# STM32WB10CCU6 register map
File version: 1.0
Registers are 32-bit, access not given, reset 0x0 unless marked. A register's access mark holds for its fields unless they carry their own. Offsets are from the block's base; [hi:lo] are bit positions; {n}, {i} and the like mark numbered series.

## WWDG
Base 0x40002C00
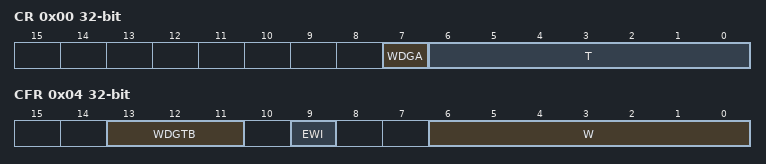
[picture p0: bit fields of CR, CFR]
0x00 CR
  [7] WDGA, [6:0] T
0x04 CFR
  [13:11] WDGTB, [9] EWI, [6:0] W
0x08 SR
  [0] EWIF

## IWDG
Base 0x40003000
0x00 KR
  [15:0] KEY
0x04 PR
  [2:0] PR
0x08 RLR
  [11:0] RL
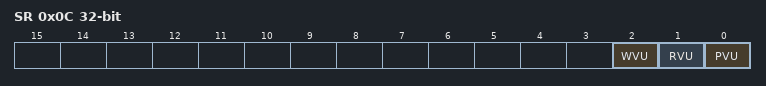
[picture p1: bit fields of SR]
0x0C SR
  [2] WVU, [1] RVU, [0] PVU
0x10 WINR
  [11:0] WIN

## I2C1
Base 0x40005400
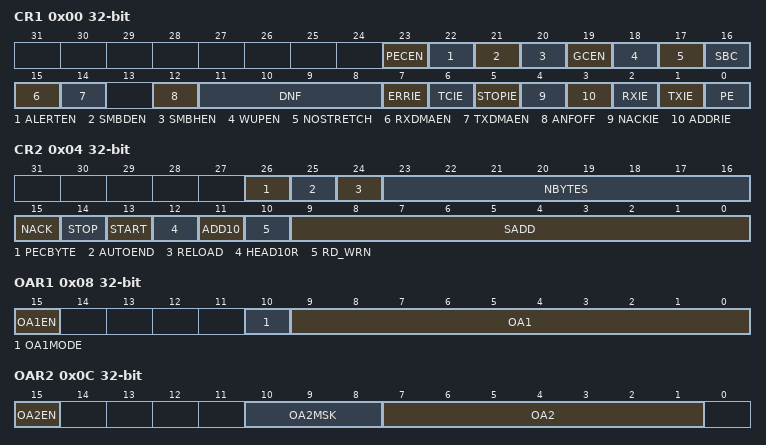
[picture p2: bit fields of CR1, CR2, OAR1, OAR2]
0x00 CR1
  [23] PECEN, [22] ALERTEN, [21] SMBDEN, [20] SMBHEN, [19] GCEN, [18] WUPEN, [17] NOSTRETCH, [16] SBC, [15] RXDMAEN, [14] TXDMAEN, [12] ANFOFF, [11:8] DNF, [7] ERRIE, [6] TCIE, [5] STOPIE, [4] NACKIE, [3] ADDRIE, [2] RXIE, [1] TXIE, [0] PE
0x04 CR2
  [26] PECBYTE, [25] AUTOEND, [24] RELOAD, [23:16] NBYTES, [15] NACK, [14] STOP, [13] START, [12] HEAD10R, [11] ADD10, [10] RD_WRN, [9:0] SADD
0x08 OAR1
  [15] OA1EN, [10] OA1MODE, [9:0] OA1
0x0C OAR2
  [15] OA2EN, [10:8] OA2MSK, [7:1] OA2
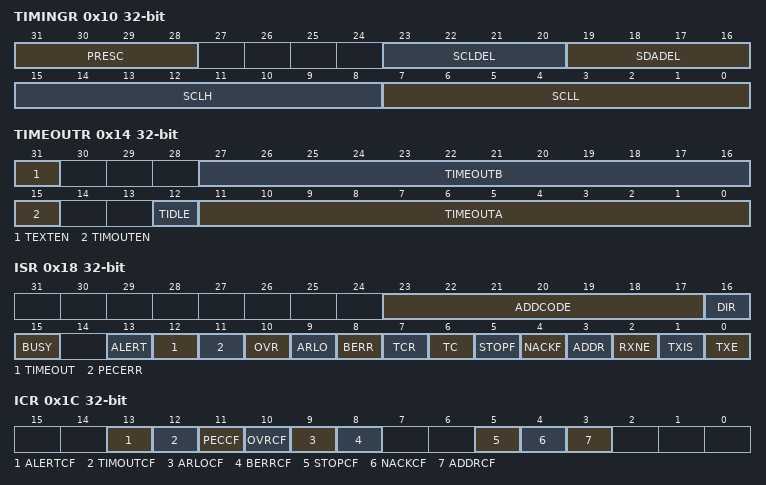
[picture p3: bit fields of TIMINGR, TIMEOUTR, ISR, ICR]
0x10 TIMINGR
  [31:28] PRESC, [23:20] SCLDEL, [19:16] SDADEL, [15:8] SCLH, [7:0] SCLL
0x14 TIMEOUTR
  [31] TEXTEN, [27:16] TIMEOUTB, [15] TIMOUTEN, [12] TIDLE, [11:0] TIMEOUTA
0x18 ISR
  [23:17] ADDCODE, [16] DIR, [15] BUSY, [13] ALERT, [12] TIMEOUT, [11] PECERR, [10] OVR, [9] ARLO, [8] BERR, [7] TCR, [6] TC, [5] STOPF, [4] NACKF, [3] ADDR, [2] RXNE, [1] TXIS, [0] TXE
0x1C ICR
  [13] ALERTCF, [12] TIMOUTCF, [11] PECCF, [10] OVRCF, [9] ARLOCF, [8] BERRCF, [5] STOPCF, [4] NACKCF, [3] ADDRCF
0x20 PECR
  [7:0] PEC
0x24 RXDR
  [7:0] RXDATA
0x28 TXDR
  [7:0] TXDATA

## LPTIM1
Base 0x40007C00
Same registers: LPTIM2 0x40009400
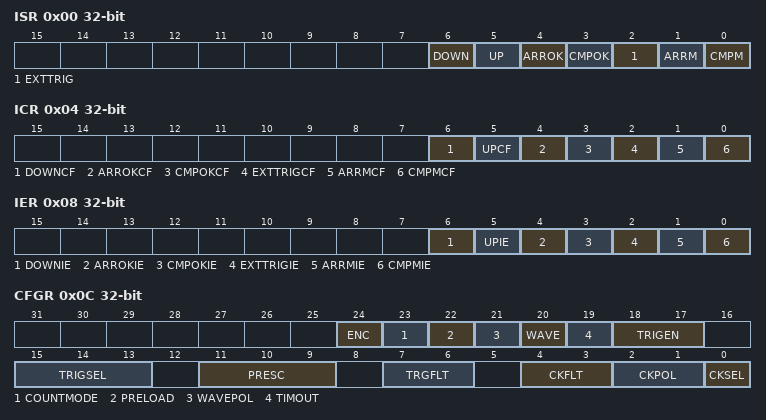
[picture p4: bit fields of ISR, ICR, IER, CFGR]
0x00 ISR
  [6] DOWN, [5] UP, [4] ARROK, [3] CMPOK, [2] EXTTRIG, [1] ARRM, [0] CMPM
0x04 ICR
  [6] DOWNCF, [5] UPCF, [4] ARROKCF, [3] CMPOKCF, [2] EXTTRIGCF, [1] ARRMCF, [0] CMPMCF
0x08 IER
  [6] DOWNIE, [5] UPIE, [4] ARROKIE, [3] CMPOKIE, [2] EXTTRIGIE, [1] ARRMIE, [0] CMPMIE
0x0C CFGR
  [24] ENC, [23] COUNTMODE, [22] PRELOAD, [21] WAVEPOL, [20] WAVE, [19] TIMOUT, [18:17] TRIGEN, [15:13] TRIGSEL, [11:9] PRESC, [7:6] TRGFLT, [4:3] CKFLT, [2:1] CKPOL, [0] CKSEL
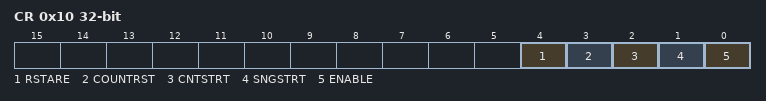
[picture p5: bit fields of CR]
0x10 CR
  [4] RSTARE, [3] COUNTRST, [2] CNTSTRT, [1] SNGSTRT, [0] ENABLE
0x14 CMP
  [15:0] CMP
0x18 ARR
  [15:0] ARR
0x1C CNT
  [15:0] CNT

## SYSCFG
Base 0x40010000
0x00 MEMRMP
  [2:0] MEM_MODE
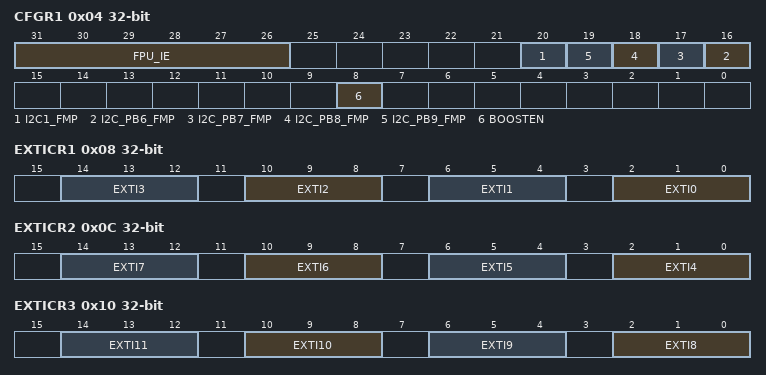
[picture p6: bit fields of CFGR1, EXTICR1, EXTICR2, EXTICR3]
0x04 CFGR1
  [31:26] FPU_IE, [20] I2C1_FMP, [n+10] I2C_PB{n}_FMP (n=6..9), [8] BOOSTEN
0x08 EXTICR1
  [4n+2:4n] EXTI{n} (n=0..3)
0x0C EXTICR2
  [4n-14:4n-16] EXTI{n} (n=4..7)
0x10 EXTICR3
  [4n-30:4n-32] EXTI{n} (n=8..11)
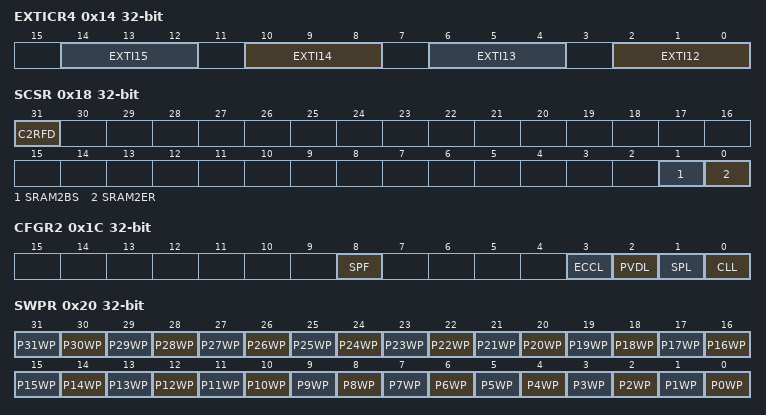
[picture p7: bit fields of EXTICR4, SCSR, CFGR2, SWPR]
0x14 EXTICR4
  [4n-46:4n-48] EXTI{n} (n=12..15)
0x18 SCSR
  [31] C2RFD, [1] SRAM2BS, [0] SRAM2ER
0x1C CFGR2
  [8] SPF, [3] ECCL, [2] PVDL, [1] SPL, [0] CLL
0x20 SWPR
  [n] P{n}WP (n=0..31)
0x24 SKR
  [7:0] KEY
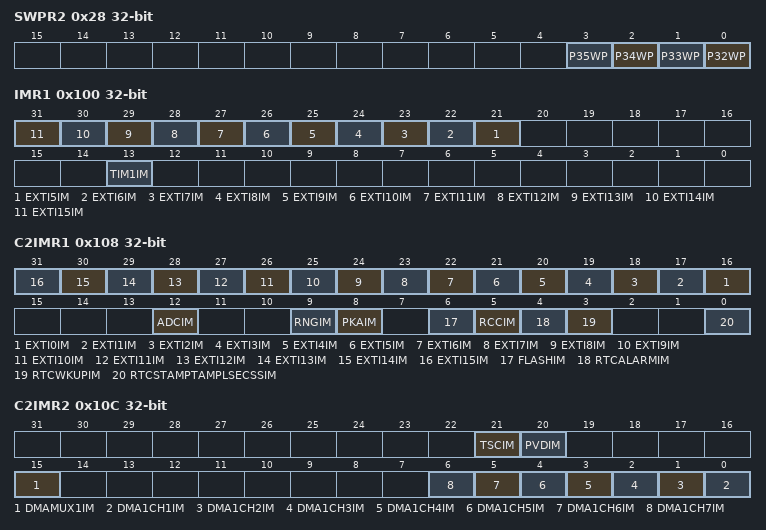
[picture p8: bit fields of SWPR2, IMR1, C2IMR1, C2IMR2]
0x28 SWPR2
  [n-32] P{n}WP (n=32..35)
0x100 IMR1
  [n+16] EXTI{n}IM (n=5..15), [13] TIM1IM
0x104 IMR2
  [20] PVDIM
0x108 C2IMR1
  [n+16] EXTI{n}IM (n=0..15), [12] ADCIM, [9] RNGIM, [8] PKAIM, [6] FLASHIM, [5] RCCIM, [4] RTCALARMIM, [3] RTCWKUPIM, [0] RTCSTAMPTAMPLSECSSIM
0x10C C2IMR2
  [21] TSCIM, [20] PVDIM, [15] DMAMUX1IM, [n-1] DMA1CH{n}IM (n=1..7)
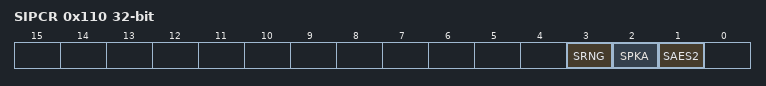
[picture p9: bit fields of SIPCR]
0x110 SIPCR
  [3] SRNG, [2] SPKA, [1] SAES2

## ADC
Base 0x40012400
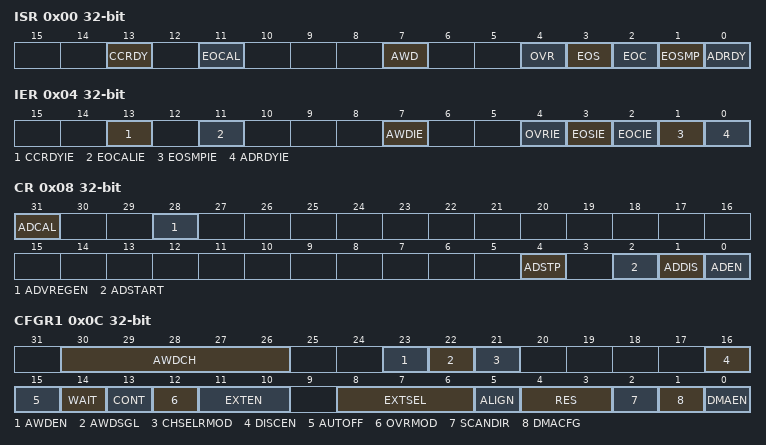
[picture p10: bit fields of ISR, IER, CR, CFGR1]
0x00 ISR
  [13] CCRDY, [11] EOCAL, [7] AWD, [4] OVR, [3] EOS, [2] EOC, [1] EOSMP, [0] ADRDY
0x04 IER
  [13] CCRDYIE, [11] EOCALIE, [7] AWDIE, [4] OVRIE, [3] EOSIE, [2] EOCIE, [1] EOSMPIE, [0] ADRDYIE
0x08 CR
  [31] ADCAL, [28] ADVREGEN, [4] ADSTP, [2] ADSTART, [1] ADDIS, [0] ADEN
0x0C CFGR1
  [30:26] AWDCH, [23] AWDEN, [22] AWDSGL, [21] CHSELRMOD, [16] DISCEN, [15] AUTOFF, [14] WAIT, [13] CONT, [12] OVRMOD, [11:10] EXTEN, [8:6] EXTSEL, [5] ALIGN, [4:3] RES, [2] SCANDIR, [1] DMACFG, [0] DMAEN
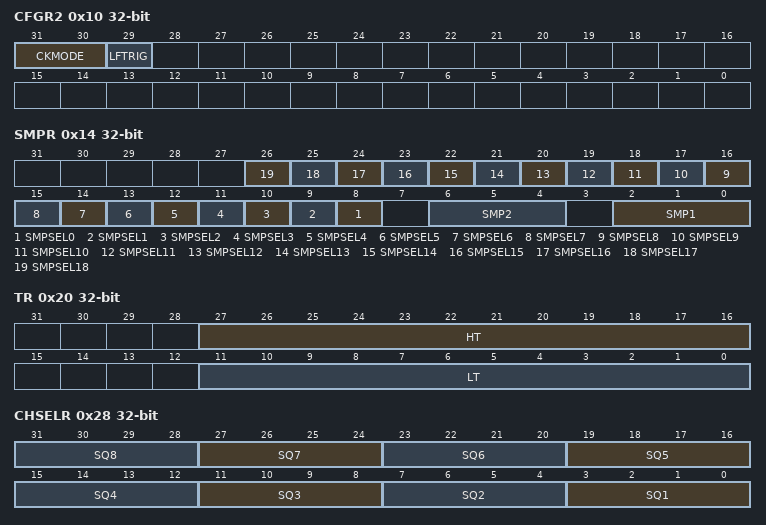
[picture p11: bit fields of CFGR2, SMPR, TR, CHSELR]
0x10 CFGR2
  [31:30] CKMODE, [29] LFTRIG
0x14 SMPR
  [n+8] SMPSEL{n} (n=0..18), [6:4] SMP2, [2:0] SMP1
0x20 TR
  [27:16] HT, [11:0] LT
0x28 CHSELR
  [4n-1:4n-4] SQ{n} (n=1..8)
0x40 DR
  [15:0] DATA
0xB4 CALFACT
  [6:0] CALFACT
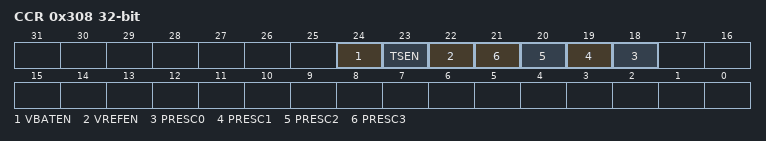
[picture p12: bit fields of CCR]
0x308 CCR
  [24] VBATEN, [23] TSEN, [22] VREFEN, [n+18] PRESC{n} (n=0..3)
